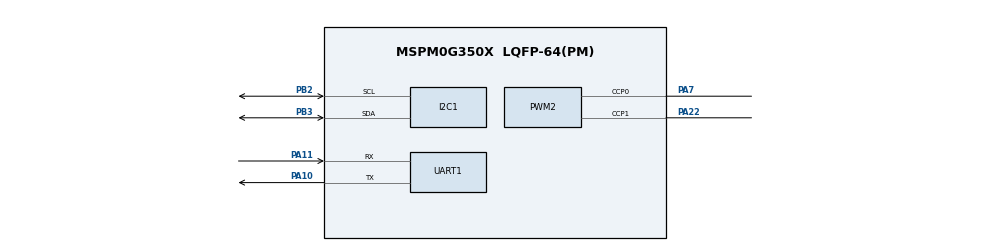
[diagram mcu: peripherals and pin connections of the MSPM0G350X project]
/**
 * @cliArgs --device "MSPM0G350X" --part "Default" --package "LQFP-64(PM)" --product "mspm0_sdk@2.04.00.06"
 * @versions {"tool":"1.21.1+3772"}
 */

/**
 * Import the modules used in this configuration.
 */
const GPIO    = scripting.addModule("/ti/driverlib/GPIO", {}, false);
const GPIO1   = GPIO.addInstance();
const GPIO2   = GPIO.addInstance();
const GPIO3   = GPIO.addInstance();
const GPIO4   = GPIO.addInstance();
const GPIO5   = GPIO.addInstance();
const GPIO6   = GPIO.addInstance();
const GPIO7   = GPIO.addInstance();
const I2C     = scripting.addModule("/ti/driverlib/I2C", {}, false);
const I2C1    = I2C.addInstance();
const PWM     = scripting.addModule("/ti/driverlib/PWM", {}, false);
const PWM1    = PWM.addInstance();
const PWM2    = PWM.addInstance();
const SYSCTL  = scripting.addModule("/ti/driverlib/SYSCTL");
const SYSTICK = scripting.addModule("/ti/driverlib/SYSTICK");
const TIMER   = scripting.addModule("/ti/driverlib/TIMER", {}, false);
const TIMER1  = TIMER.addInstance();
const UART    = scripting.addModule("/ti/driverlib/UART", {}, false);
const UART1   = UART.addInstance();

/**
 * Write custom configuration values to the imported modules.
 */
const divider5       = system.clockTree["PLL_CLK1_DIV"];
divider5.divideValue = 4;

const divider6       = system.clockTree["PLL_CLK2X_DIV"];
divider6.divideValue = 4;

const divider7       = system.clockTree["PLL_PDIV"];
divider7.divideValue = 2;

const divider9       = system.clockTree["UDIV"];
divider9.divideValue = 2;

const gate7  = system.clockTree["MFCLKGATE"];
gate7.enable = true;

const gate8  = system.clockTree["MFPCLKGATE"];
gate8.enable = true;

const multiplier2         = system.clockTree["PLL_QDIV"];
multiplier2.multiplyValue = 10;

const mux4       = system.clockTree["EXHFMUX"];
mux4.inputSelect = "EXHFMUX_XTAL";

const mux8       = system.clockTree["HSCLKMUX"];
mux8.inputSelect = "HSCLKMUX_SYSPLL2X";

GPIO1.$name                              = "MPU6050";
GPIO1.associatedPins[0].$name            = "INT_PIN";
GPIO1.associatedPins[0].direction        = "INPUT";
GPIO1.associatedPins[0].internalResistor = "PULL_UP";
GPIO1.associatedPins[0].interruptEn      = true;
GPIO1.associatedPins[0].polarity         = "FALL";
GPIO1.associatedPins[0].assignedPort     = "PORTB";
GPIO1.associatedPins[0].assignedPin      = "0";

const Board = scripting.addModule("/ti/driverlib/Board", {}, false);

GPIO2.$name                          = "OLED";
GPIO2.associatedPins.create(2);
GPIO2.associatedPins[0].$name        = "OLED_SDA";
GPIO2.associatedPins[0].assignedPort = "PORTB";
GPIO2.associatedPins[0].assignedPin  = "15";
GPIO2.associatedPins[1].assignedPort = "PORTA";
GPIO2.associatedPins[1].assignedPin  = "17";
GPIO2.associatedPins[1].$name        = "OLED_SCL";

GPIO3.$name                              = "Trail";
GPIO3.associatedPins.create(2);
GPIO3.associatedPins[0].$name            = "Trail_DAT";
GPIO3.associatedPins[0].direction        = "INPUT";
GPIO3.associatedPins[0].internalResistor = "PULL_UP";
GPIO3.associatedPins[0].assignedPort     = "PORTA";
GPIO3.associatedPins[0].assignedPin      = "12";
GPIO3.associatedPins[1].$name            = "Trail_CLK";
GPIO3.associatedPins[1].direction        = "INPUT";
GPIO3.associatedPins[1].internalResistor = "PULL_UP";
GPIO3.associatedPins[1].assignedPort     = "PORTA";
GPIO3.associatedPins[1].assignedPin      = "13";

GPIO4.$name                         = "Register";
GPIO4.port                          = "PORTA";
GPIO4.associatedPins.create(3);
GPIO4.associatedPins[0].$name       = "TCP";
GPIO4.associatedPins[0].assignedPin = "14";
GPIO4.associatedPins[1].$name       = "HCP";
GPIO4.associatedPins[1].assignedPin = "15";
GPIO4.associatedPins[2].$name       = "DS";
GPIO4.associatedPins[2].assignedPin = "25";

GPIO5.$name                              = "Key";
GPIO5.port                               = "PORTB";
GPIO5.associatedPins.create(4);
GPIO5.associatedPins[0].$name            = "Key1";
GPIO5.associatedPins[0].direction        = "INPUT";
GPIO5.associatedPins[0].internalResistor = "PULL_UP";
GPIO5.associatedPins[0].assignedPin      = "12";
GPIO5.associatedPins[1].$name            = "Key2";
GPIO5.associatedPins[1].direction        = "INPUT";
GPIO5.associatedPins[1].internalResistor = "PULL_UP";
GPIO5.associatedPins[1].assignedPin      = "8";
GPIO5.associatedPins[2].$name            = "Key3";
GPIO5.associatedPins[2].direction        = "INPUT";
GPIO5.associatedPins[2].internalResistor = "PULL_UP";
GPIO5.associatedPins[2].assignedPin      = "9";
GPIO5.associatedPins[3].$name            = "Key4";
GPIO5.associatedPins[3].direction        = "INPUT";
GPIO5.associatedPins[3].internalResistor = "PULL_UP";
GPIO5.associatedPins[3].assignedPin      = "10";

GPIO6.$name                               = "Encoder";
GPIO6.port                                = "PORTB";
GPIO6.associatedPins.create(8);
GPIO6.associatedPins[0].$name             = "L1_E1";
GPIO6.associatedPins[0].direction         = "INPUT";
GPIO6.associatedPins[0].assignedPin       = "4";
GPIO6.associatedPins[0].interruptEn       = true;
GPIO6.associatedPins[0].interruptPriority = "1";
GPIO6.associatedPins[0].polarity          = "RISE";
GPIO6.associatedPins[1].$name             = "L1_E2";
GPIO6.associatedPins[1].direction         = "INPUT";
GPIO6.associatedPins[1].assignedPin       = "5";
GPIO6.associatedPins[1].interruptEn       = true;
GPIO6.associatedPins[1].interruptPriority = "1";
GPIO6.associatedPins[1].polarity          = "RISE";
GPIO6.associatedPins[2].$name             = "L2_E1";
GPIO6.associatedPins[2].direction         = "INPUT";
GPIO6.associatedPins[2].interruptEn       = true;
GPIO6.associatedPins[2].interruptPriority = "1";
GPIO6.associatedPins[2].polarity          = "RISE";
GPIO6.associatedPins[2].assignedPin       = "6";
GPIO6.associatedPins[3].$name             = "L2_E2";
GPIO6.associatedPins[3].direction         = "INPUT";
GPIO6.associatedPins[3].interruptEn       = true;
GPIO6.associatedPins[3].interruptPriority = "1";
GPIO6.associatedPins[3].polarity          = "RISE";
GPIO6.associatedPins[3].assignedPin       = "7";
GPIO6.associatedPins[4].$name             = "R1_E1";
GPIO6.associatedPins[4].direction         = "INPUT";
GPIO6.associatedPins[4].interruptEn       = true;
GPIO6.associatedPins[4].interruptPriority = "1";
GPIO6.associatedPins[4].polarity          = "RISE";
GPIO6.associatedPins[4].assignedPin       = "23";
GPIO6.associatedPins[5].$name             = "R1_E2";
GPIO6.associatedPins[5].direction         = "INPUT";
GPIO6.associatedPins[5].interruptEn       = true;
GPIO6.associatedPins[5].interruptPriority = "1";
GPIO6.associatedPins[5].polarity          = "RISE";
GPIO6.associatedPins[5].assignedPin       = "13";
GPIO6.associatedPins[6].$name             = "R2_E1";
GPIO6.associatedPins[6].direction         = "INPUT";
GPIO6.associatedPins[6].interruptEn       = true;
GPIO6.associatedPins[6].interruptPriority = "1";
GPIO6.associatedPins[6].polarity          = "RISE";
GPIO6.associatedPins[6].assignedPin       = "19";
GPIO6.associatedPins[7].$name             = "R2_E2";
GPIO6.associatedPins[7].direction         = "INPUT";
GPIO6.associatedPins[7].interruptEn       = true;
GPIO6.associatedPins[7].interruptPriority = "1";
GPIO6.associatedPins[7].polarity          = "RISE";
GPIO6.associatedPins[7].assignedPin       = "18";

GPIO7.$name                         = "Buzzer";
GPIO7.port                          = "PORTA";
GPIO7.associatedPins[0].$name       = "PIN_0";
GPIO7.associatedPins[0].assignedPin = "27";

I2C1.$name                           = "I2C_0";
I2C1.basicEnableController           = true;
I2C1.basicControllerStandardBusSpeed = "Fast";
I2C1.peripheral.sdaPin.$assign       = "PB3";
I2C1.peripheral.sclPin.$assign       = "PB2";
I2C1.sdaPinConfig.$name              = "ti_driverlib_gpio_GPIOPinGeneric2";
I2C1.sclPinConfig.$name              = "ti_driverlib_gpio_GPIOPinGeneric3";

PWM1.clockDivider                       = 2;
PWM1.timerCount                         = 4000;
PWM1.timerStartTimer                    = true;
PWM1.$name                              = "PWM_R";
PWM1.peripheral.$assign                 = "TIMA0";
PWM1.PWM_CHANNEL_0.$name                = "ti_driverlib_pwm_PWMTimerCC0";
PWM1.PWM_CHANNEL_1.$name                = "ti_driverlib_pwm_PWMTimerCC1";
PWM1.ccp0PinConfig.direction            = scripting.forceWrite("OUTPUT");
PWM1.ccp0PinConfig.hideOutputInversion  = scripting.forceWrite(false);
PWM1.ccp0PinConfig.onlyInternalResistor = scripting.forceWrite(false);
PWM1.ccp0PinConfig.passedPeripheralType = scripting.forceWrite("Digital");
PWM1.ccp0PinConfig.$name                = "ti_driverlib_gpio_GPIOPinGeneric6";
PWM1.ccp1PinConfig.direction            = scripting.forceWrite("OUTPUT");
PWM1.ccp1PinConfig.hideOutputInversion  = scripting.forceWrite(false);
PWM1.ccp1PinConfig.onlyInternalResistor = scripting.forceWrite(false);
PWM1.ccp1PinConfig.passedPeripheralType = scripting.forceWrite("Digital");
PWM1.ccp1PinConfig.$name                = "ti_driverlib_gpio_GPIOPinGeneric7";

PWM2.timerCount                         = 4000;
PWM2.timerStartTimer                    = true;
PWM2.$name                              = "PWM_L";
PWM2.peripheral.$assign                 = "TIMG8";
PWM2.peripheral.ccp0Pin.$assign         = "PA7";
PWM2.peripheral.ccp1Pin.$assign         = "PA22";
PWM2.PWM_CHANNEL_0.$name                = "ti_driverlib_pwm_PWMTimerCC2";
PWM2.PWM_CHANNEL_1.$name                = "ti_driverlib_pwm_PWMTimerCC3";
PWM2.ccp0PinConfig.direction            = scripting.forceWrite("OUTPUT");
PWM2.ccp0PinConfig.hideOutputInversion  = scripting.forceWrite(false);
PWM2.ccp0PinConfig.onlyInternalResistor = scripting.forceWrite(false);
PWM2.ccp0PinConfig.passedPeripheralType = scripting.forceWrite("Digital");
PWM2.ccp0PinConfig.$name                = "ti_driverlib_gpio_GPIOPinGeneric8";
PWM2.ccp1PinConfig.direction            = scripting.forceWrite("OUTPUT");
PWM2.ccp1PinConfig.hideOutputInversion  = scripting.forceWrite(false);
PWM2.ccp1PinConfig.onlyInternalResistor = scripting.forceWrite(false);
PWM2.ccp1PinConfig.passedPeripheralType = scripting.forceWrite("Digital");
PWM2.ccp1PinConfig.$name                = "ti_driverlib_gpio_GPIOPinGeneric9";

SYSCTL.forceDefaultClkConfig = true;
SYSCTL.clockTreeEn           = true;

SYSTICK.systickEnable = true;
SYSTICK.periodEnable  = true;
SYSTICK.period        = 16777215;

TIMER1.$name              = "TIMER_0";
TIMER1.timerClkDiv        = 2;
TIMER1.timerStartTimer    = true;
TIMER1.interrupts         = ["ZERO"];
TIMER1.timerMode          = "PERIODIC";
TIMER1.interruptPriority  = "0";
TIMER1.timerPeriod        = "10 ms";
TIMER1.peripheral.$assign = "TIMG12";

UART1.$name                    = "UART_0";
UART1.targetBaudRate           = 115200;
UART1.enabledInterrupts        = ["RX"];
UART1.peripheral.rxPin.$assign = "PA11";
UART1.peripheral.txPin.$assign = "PA10";
UART1.txPinConfig.$name        = "ti_driverlib_gpio_GPIOPinGeneric0";
UART1.rxPinConfig.$name        = "ti_driverlib_gpio_GPIOPinGeneric1";

/**
 * Pinmux solution for unlocked pins/peripherals. This ensures that minor changes to the automatic solver in a future
 * version of the tool will not impact the pinmux you originally saw.  These lines can be completely deleted in order to
 * re-solve from scratch.
 */
GPIO1.associatedPins[0].pin.$suggestSolution = "PB0";
Board.peripheral.$suggestSolution            = "DEBUGSS";
Board.peripheral.swclkPin.$suggestSolution   = "PA20";
Board.peripheral.swdioPin.$suggestSolution   = "PA19";
GPIO2.associatedPins[0].pin.$suggestSolution = "PB15";
GPIO2.associatedPins[1].pin.$suggestSolution = "PA17";
GPIO3.associatedPins[0].pin.$suggestSolution = "PA12";
GPIO3.associatedPins[1].pin.$suggestSolution = "PA13";
GPIO4.associatedPins[0].pin.$suggestSolution = "PA14";
GPIO4.associatedPins[1].pin.$suggestSolution = "PA15";
GPIO4.associatedPins[2].pin.$suggestSolution = "PA25";
GPIO5.associatedPins[0].pin.$suggestSolution = "PB12";
GPIO5.associatedPins[1].pin.$suggestSolution = "PB8";
GPIO5.associatedPins[2].pin.$suggestSolution = "PB9";
GPIO5.associatedPins[3].pin.$suggestSolution = "PB10";
GPIO6.associatedPins[0].pin.$suggestSolution = "PB4";
GPIO6.associatedPins[1].pin.$suggestSolution = "PB5";
GPIO6.associatedPins[2].pin.$suggestSolution = "PB6";
GPIO6.associatedPins[3].pin.$suggestSolution = "PB7";
GPIO6.associatedPins[4].pin.$suggestSolution = "PB23";
GPIO6.associatedPins[5].pin.$suggestSolution = "PB13";
GPIO6.associatedPins[6].pin.$suggestSolution = "PB19";
GPIO6.associatedPins[7].pin.$suggestSolution = "PB18";
GPIO7.associatedPins[0].pin.$suggestSolution = "PA27";
I2C1.peripheral.$suggestSolution             = "I2C1";
PWM1.peripheral.ccp0Pin.$suggestSolution     = "PA0";
PWM1.peripheral.ccp1Pin.$suggestSolution     = "PA1";
UART1.peripheral.$suggestSolution            = "UART0";
